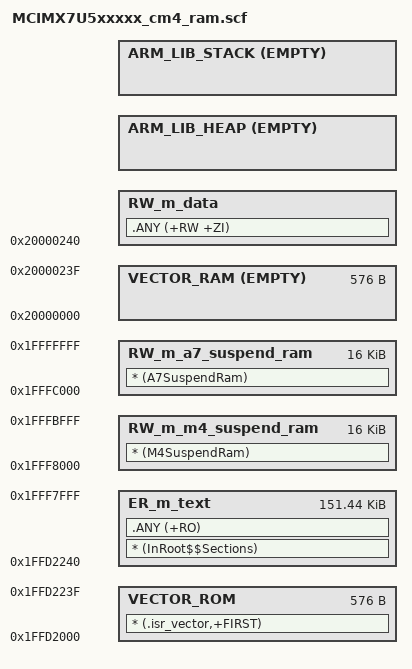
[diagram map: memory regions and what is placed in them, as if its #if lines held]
#!armclang --target=arm-arm-none-eabi -mcpu=cortex-m4 -E -x c
/*
** ###################################################################
**     Processors:          MCIMX7U5CVP06
**                          MCIMX7U5DVK07
**                          MCIMX7U5DVP07
**
**     Compiler:            Keil ARM C/C++ Compiler
**     Reference manual:    IMX7ULPRM, Rev. 0, Nov. 2018
**     Version:             rev. 7.0, 2018-11-05
**     Build:               b200331
**
**     Abstract:
**         Linker file for the Keil ARM C/C++ Compiler
**
**     Copyright 2016 Freescale Semiconductor, Inc.
**     Copyright 2016-2020 NXP
**     All rights reserved.
**
**     SPDX-License-Identifier: BSD-3-Clause
**
**     http:                 www.nxp.com
**     mail:                 support@nxp.com
**
** ###################################################################
*/

/* Memory region from [0x1FFD0000-0x1FFD1FFF] is reserved for ROM code */

#if (defined(__ram_vector_table__))
  #define __ram_vector_table_size__    0x00000240
#else
  #define __ram_vector_table_size__    0x00000000
#endif

#define m_interrupts_start             0x1FFD2000
#define m_interrupts_size              0x00000240

#define m_text_start                   0x1FFD2240
#define m_text_size                    0x00025DC0

#define m_m4_suspend_ram_start         0x1FFF8000
#define m_m4_suspend_ram_size          0x00004000

#define m_a7_suspend_ram_start         0x1FFFC000
#define m_a7_suspend_ram_size          0x00004000

#define m_interrupts_ram_start         0x20000000
#define m_interrupts_ram_size          __ram_vector_table_size__

#define m_data_start                   (m_interrupts_ram_start + m_interrupts_ram_size)
#define m_data_size                    (0x00010000 - m_interrupts_ram_size)

/* Sizes */
#if (defined(__stack_size__))
  #define Stack_Size                   __stack_size__
#else
  #define Stack_Size                   0x0400
#endif

#if (defined(__heap_size__))
  #define Heap_Size                    __heap_size__
#else
  #define Heap_Size                    0x0400
#endif

LR_m_text m_interrupts_start m_text_start+m_text_size-m_interrupts_start { ; load region size_region
  VECTOR_ROM m_interrupts_start m_interrupts_size { ; load address = execution address
    * (.isr_vector,+FIRST)
  }
  ER_m_text m_text_start m_text_size { ; load address = execution address
    * (InRoot$$Sections)
    .ANY (+RO)
  }
  RW_m_m4_suspend_ram m_m4_suspend_ram_start m_m4_suspend_ram_size { ; RW data
    * (M4SuspendRam)
  }
  RW_m_a7_suspend_ram m_a7_suspend_ram_start m_a7_suspend_ram_size { ; RW data
    * (A7SuspendRam)
  }

#if (defined(__ram_vector_table__))
  VECTOR_RAM m_interrupts_ram_start EMPTY m_interrupts_ram_size {
  }
#else
  VECTOR_RAM m_interrupts_start EMPTY 0 {
  }
#endif
  RW_m_data m_data_start m_data_size-Stack_Size-Heap_Size { ; RW data
    .ANY (+RW +ZI)
  }
  ARM_LIB_HEAP +0 EMPTY Heap_Size {    ; Heap region growing up
  }
  ARM_LIB_STACK m_data_start+m_data_size EMPTY -Stack_Size { ; Stack region growing down
  }
}
